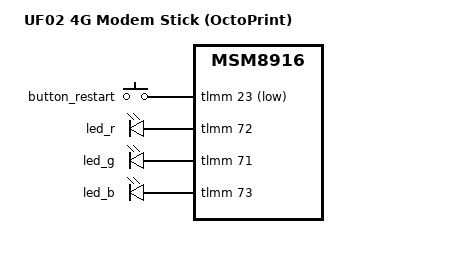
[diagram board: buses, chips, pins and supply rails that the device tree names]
// SPDX-License-Identifier: GPL-2.0-only
/*
 * OctoPrint profile for the UF02 class device.
 * Disables LTE modem remoteproc + firmware memory and Venus video decode
 * so the constrained device has more RAM available for OctoPrint.
 * WiFi (wcnss) is intentionally kept enabled.
 */

/dts-v1/;

#include "msm8916-ufi.dtsi"

#include <dt-bindings/leds/common.h>

/ {
	model = "UF02 4G Modem Stick (OctoPrint)";
	compatible = "uf02,250605v0s-octoprint", "uf02,250605v0s", "qcom,msm8916";
};

&button_restart {
	gpios = <&tlmm 23 GPIO_ACTIVE_LOW>;
};

&led_r {
	gpios = <&tlmm 72 GPIO_ACTIVE_HIGH>;
};

&led_g {
	function = LED_FUNCTION_WAN;
	gpios = <&tlmm 71 GPIO_ACTIVE_HIGH>;
};

&led_b {
	function = LED_FUNCTION_WLAN;
	gpios = <&tlmm 73 GPIO_ACTIVE_HIGH>;
};

&button_default {
	pins = "gpio23";
	bias-pull-up;
};

&gpio_leds_default {
	pins = "gpio71", "gpio72", "gpio73";
};

/* ----- LTE modem: disable remoteproc and firmware reserved memory ----- */

&mpss {
	status = "disabled";
};

&mpss_mem {
	status = "disabled";
};

&mba_mem {
	status = "disabled";
};

/* BAM data multiplexer is only useful with the modem running */
&bam_dmux {
	status = "disabled";
};

&bam_dmux_dma {
	status = "disabled";
};

/* ----- Venus video decode: disable remoteproc and reserved memory ----- */

&venus {
	status = "disabled";
};

&venus_mem {
	status = "disabled";
};
